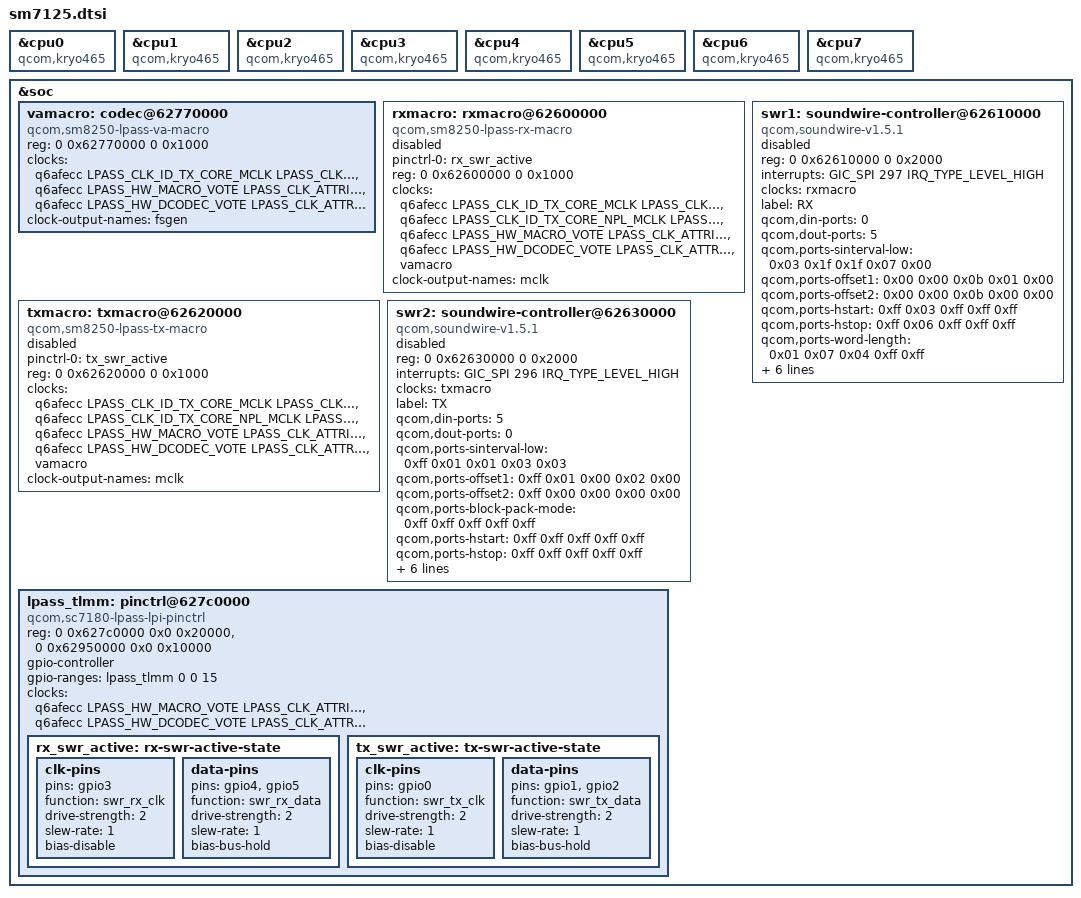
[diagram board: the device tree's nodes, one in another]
// SPDX-License-Identifier: GPL-2.0
/*
 * Copyright (c) 2021, The Linux Foundation. All rights reserved.
 */

#include "sc7180.dtsi"

/* SM7125 uses Kryo 465 instead of Kryo 468 */
&cpu0 { compatible = "qcom,kryo465"; };
&cpu1 { compatible = "qcom,kryo465"; };
&cpu2 { compatible = "qcom,kryo465"; };
&cpu3 { compatible = "qcom,kryo465"; };
&cpu4 { compatible = "qcom,kryo465"; };
&cpu5 { compatible = "qcom,kryo465"; };
&cpu6 { compatible = "qcom,kryo465"; };
&cpu7 { compatible = "qcom,kryo465"; };

&soc {
	vamacro: codec@62770000 {
		compatible = "qcom,sm8250-lpass-va-macro";
		reg = <0 0x62770000 0 0x1000>;
		clocks = <&q6afecc LPASS_CLK_ID_TX_CORE_MCLK LPASS_CLK_ATTRIBUTE_COUPLE_NO>,
			<&q6afecc LPASS_HW_MACRO_VOTE LPASS_CLK_ATTRIBUTE_COUPLE_NO>,
			<&q6afecc LPASS_HW_DCODEC_VOTE LPASS_CLK_ATTRIBUTE_COUPLE_NO>;

		clock-names = "mclk", "macro", "dcodec";

		#clock-cells = <0>;
		clock-output-names = "fsgen";
		#sound-dai-cells = <1>;
	};

	rxmacro: rxmacro@62600000 {
		pinctrl-names = "default";
		pinctrl-0 = <&rx_swr_active>;
		compatible = "qcom,sm8250-lpass-rx-macro";
		reg = <0 0x62600000 0 0x1000>;
		status = "disabled";

		clocks = <&q6afecc LPASS_CLK_ID_TX_CORE_MCLK LPASS_CLK_ATTRIBUTE_COUPLE_NO>,
				<&q6afecc LPASS_CLK_ID_TX_CORE_NPL_MCLK LPASS_CLK_ATTRIBUTE_COUPLE_NO>,
				<&q6afecc LPASS_HW_MACRO_VOTE LPASS_CLK_ATTRIBUTE_COUPLE_NO>,
				<&q6afecc LPASS_HW_DCODEC_VOTE LPASS_CLK_ATTRIBUTE_COUPLE_NO>,
				<&vamacro>;

		clock-names = "mclk", "npl", "macro", "dcodec", "fsgen";

		#clock-cells = <0>;
		clock-output-names = "mclk";
		#sound-dai-cells = <1>;
	};

	swr1: soundwire-controller@62610000 {
		reg = <0 0x62610000 0 0x2000>;
		compatible = "qcom,soundwire-v1.5.1";
		status = "disabled";
		interrupts = <GIC_SPI 297 IRQ_TYPE_LEVEL_HIGH>;

		clocks = <&rxmacro>;
		clock-names = "iface";
		label = "RX";

		qcom,din-ports = <0>;
		qcom,dout-ports = <5>;
		qcom,ports-sinterval-low =	/bits/ 8 <0x03 0x1f 0x1f 0x07 0x00>;
		qcom,ports-offset1 =		/bits/ 8 <0x00 0x00 0x0b 0x01 0x00>;
		qcom,ports-offset2 =		/bits/ 8 <0x00 0x00 0x0b 0x00 0x00>;
		qcom,ports-hstart =		/bits/ 8 <0xff 0x03 0xff 0xff 0xff>;
		qcom,ports-hstop =		/bits/ 8 <0xff 0x06 0xff 0xff 0xff>;
		qcom,ports-word-length =	/bits/ 8 <0x01 0x07 0x04 0xff 0xff>;
		qcom,ports-block-pack-mode =	/bits/ 8 <0xff 0x00 0x01 0xff 0xff>;
		qcom,ports-lane-control =	/bits/ 8 <0x01 0x00 0x00 0x00 0x00>;
		qcom,ports-block-group-count =	/bits/ 8 <0xff 0xff 0xff 0xff 0x00>;

		#sound-dai-cells = <1>;
		#address-cells = <2>;
		#size-cells = <0>;
	};

	txmacro: txmacro@62620000 {
		pinctrl-names = "default";
		pinctrl-0 = <&tx_swr_active>;
		compatible = "qcom,sm8250-lpass-tx-macro";
		reg = <0 0x62620000 0 0x1000>;
		status = "disabled";

		clocks = <&q6afecc LPASS_CLK_ID_TX_CORE_MCLK LPASS_CLK_ATTRIBUTE_COUPLE_NO>,
				<&q6afecc LPASS_CLK_ID_TX_CORE_NPL_MCLK LPASS_CLK_ATTRIBUTE_COUPLE_NO>,
				<&q6afecc LPASS_HW_MACRO_VOTE LPASS_CLK_ATTRIBUTE_COUPLE_NO>,
				<&q6afecc LPASS_HW_DCODEC_VOTE LPASS_CLK_ATTRIBUTE_COUPLE_NO>,
				<&vamacro>;

		clock-names = "mclk", "npl", "macro", "dcodec", "fsgen";

		#clock-cells = <0>;
		clock-output-names = "mclk";
		#sound-dai-cells = <1>;
	};

	swr2: soundwire-controller@62630000 {
		reg = <0 0x62630000 0 0x2000>;
		compatible = "qcom,soundwire-v1.5.1";
		status = "disabled";
		interrupts = <GIC_SPI 296 IRQ_TYPE_LEVEL_HIGH>;

		clocks = <&txmacro>;
		clock-names = "iface";
		label = "TX";

		qcom,din-ports = <5>;
		qcom,dout-ports = <0>;
		qcom,ports-sinterval-low =	/bits/ 8 <0xff 0x01 0x01 0x03 0x03>;
		qcom,ports-offset1 =		/bits/ 8 <0xff 0x01 0x00 0x02 0x00>;
		qcom,ports-offset2 =		/bits/ 8 <0xff 0x00 0x00 0x00 0x00>;
		qcom,ports-block-pack-mode =	/bits/ 8 <0xff 0xff 0xff 0xff 0xff>;
		qcom,ports-hstart =		/bits/ 8 <0xff 0xff 0xff 0xff 0xff>;
		qcom,ports-hstop =		/bits/ 8 <0xff 0xff 0xff 0xff 0xff>;
		qcom,ports-word-length =	/bits/ 8 <0xff 0xff 0xff 0xff 0xff>;
		qcom,ports-block-group-count =	/bits/ 8 <0xff 0xff 0xff 0xff 0xff>;
		qcom,ports-lane-control =	/bits/ 8 <0xff 0x00 0x01 0x00 0x01>;

		#sound-dai-cells = <1>;
		#address-cells = <2>;
		#size-cells = <0>;
	};

	lpass_tlmm: pinctrl@627c0000 {
		compatible = "qcom,sc7180-lpass-lpi-pinctrl", "qcom,sc7280-lpass-lpi-pinctrl";
		reg = <0 0x627c0000 0x0 0x20000>,
			<0 0x62950000 0x0 0x10000>;

		gpio-controller;
		#gpio-cells = <2>;
		gpio-ranges = <&lpass_tlmm 0 0 15>;

		clocks = <&q6afecc LPASS_HW_MACRO_VOTE LPASS_CLK_ATTRIBUTE_COUPLE_NO>,
			<&q6afecc LPASS_HW_DCODEC_VOTE LPASS_CLK_ATTRIBUTE_COUPLE_NO>;
		clock-names = "core", "audio";

		rx_swr_active: rx-swr-active-state {
			clk-pins {
				pins = "gpio3";
				function = "swr_rx_clk";
				drive-strength = <2>;
				slew-rate = <1>;
				bias-disable;
			};

			data-pins {
				pins = "gpio4", "gpio5";
				function = "swr_rx_data";
				drive-strength = <2>;
				slew-rate = <1>;
				bias-bus-hold;
			};
		};

		tx_swr_active: tx-swr-active-state {
			clk-pins {
				pins = "gpio0";
				function = "swr_tx_clk";
				drive-strength = <2>;
				slew-rate = <1>;
				bias-disable;
			};

			data-pins {
				pins = "gpio1", "gpio2";
				function = "swr_tx_data";
				drive-strength = <2>;
				slew-rate = <1>;
				bias-bus-hold;
			};
		};
	};
};
